# Cortex_M42 register map
Vendor: Arm Ltd.; Series: ARMv8.1-M Mainline; File version: 1.0.0
CPU: CM42 r0p0, little endian, MPU, FPU, double-precision FPU, DSP, 8 interrupt priority bits
Registers are 32-bit, read-write, reset 0x0 unless marked. A register's access mark holds for its fields unless they carry their own. Offsets are from the block's base; [hi:lo] are bit positions; {n}, {i} and the like mark numbered series.

## DIB — Debug Identification Block (ARMv8-M): software lock, debug authentication status and the SCS CoreSight architecture and type IDs.
Base 0xE000EFB0
Same registers: DIB_NS 0xE002EFB0
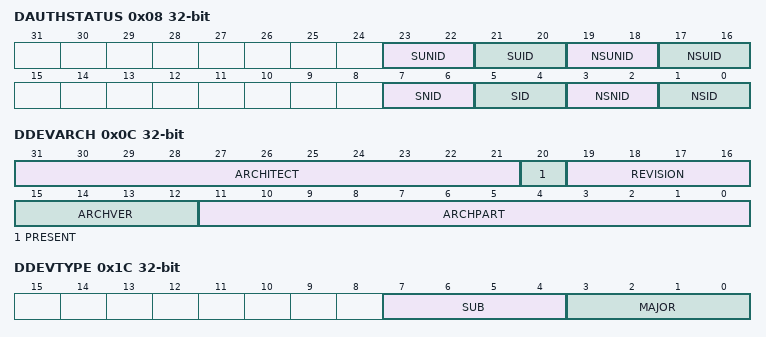
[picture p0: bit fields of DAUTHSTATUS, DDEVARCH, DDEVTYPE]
0x08 DAUTHSTATUS ro — Debug Authentication Status Register: which kinds of debug (invasive/non-invasive, Secure/Non-secure, unprivileged) are currently enabled.
  [23:22] SUNID — Secure unprivileged non-invasive debug: 2 = disabled, 3 = enabled.
  [21:20] SUID — Secure unprivileged invasive debug: 2 = disabled, 3 = enabled.
  [19:18] NSUNID — Non-secure unprivileged non-invasive debug: 2 = disabled, 3 = enabled.
  [17:16] NSUID — Non-secure unprivileged invasive debug (ARMv8.1-M UDE): 2 = disabled, 3 = enabled.
  [7:6] SNID — Secure non-invasive debug: 0 = not implemented, 2 = disabled, 3 = enabled.
  [5:4] SID — Secure invasive debug: 0 = not implemented, 2 = disabled, 3 = enabled.
  [3:2] NSNID — Non-secure non-invasive debug (trace): 0 = not implemented, 2 = disabled, 3 = enabled.
  [1:0] NSID — Non-secure invasive debug: 0 = not implemented, 2 = disabled, 3 = enabled.
0x0C DDEVARCH ro — SCS Device Architecture Register: CoreSight ARCHID of the debug architecture (0x2A04 = ARMv8-M debug) and the architect (Arm, 0x23B).
  [31:21] ARCHITECT — JEP106 code of the architect: 0x23B = Arm.
  [20] PRESENT — 1 = DDEVARCH is present and its contents are valid.
  [19:16] REVISION — Architecture revision.
  [15:12] ARCHVER — Architecture version: 2 = ARMv8-M debug architecture.
  [11:0] ARCHPART — Architecture part: 0xA04 = M-profile system control space (with ARCHVER 2 -> ARCHID 0x2A04, ARMv8-M debug).
0x1C DDEVTYPE ro — SCS Device Type Register: CoreSight major/sub type of the SCS (0x00 = processor system control).
  [7:4] SUB — Sub type: 0 for the SCS.
  [3:0] MAJOR — Major type: 0 = miscellaneous / processor system control.

## PWRMODCTL — Power Mode Control (Cortex-M55/M85/M52): the low-power state (ON / retention / OFF) requested for the core, EPU and RAM power domains when the processor sleeps.
Base 0xE001E300
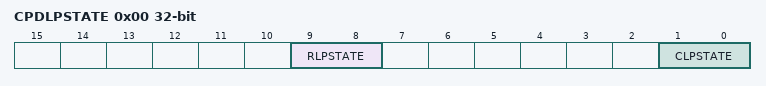
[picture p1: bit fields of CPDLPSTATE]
0x00 CPDLPSTATE — Core Power Domain Low Power State Register: the power state requested for the core, EPU (FPU/MVE) and RAM domains on deep sleep.
  [9:8] RLPSTATE — RAM (caches/TCM) low-power state: 0 = ON, 2 = retention, 3 = OFF.
  [1:0] CLPSTATE — Core low-power state requested on deep sleep: 0 = ON, 1 = ON with the clock stopped, 2 = retention, 3 = OFF.
0x04 DPDLPSTATE — Debug Power Domain Low Power State Register: the power state requested for the debug domain.
  [1:0] DLPSTATE — Debug power domain low-power state: 0 = ON, 2 = retention, 3 = OFF.

## EWIC_ISA — EWIC Interrupt Status Access: the processor-side view of the EWIC - set an event pending and read back the mask configuration.
Base 0xE001E400
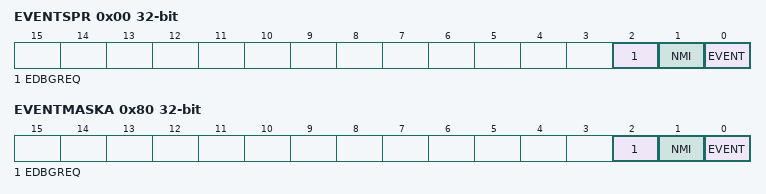
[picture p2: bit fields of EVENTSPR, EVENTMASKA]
0x00 EVENTSPR wo — Event Set Pending Register: software writes to latch an event as if it had arrived.
  [2] EDBGREQ — Write 1 to latch an external debug request.
  [1] NMI — Write 1 to latch an NMI.
  [0] EVENT — Write 1 to latch an EVENT.
0x80 EVENTMASKA ro — Event Mask A Register: read-only copy of EWIC_MASKA.
  [2] EDBGREQ — Wake on external debug request is enabled.
  [1] NMI — Wake on NMI is enabled.
  [0] EVENT — Wake on EVENT is enabled.
{0x80+4i} EVENTMASK{i} (i=1..15) ro — Event Mask Register n: read-only copy of EWIC_MASKn.
  [31:0] IRQ — Bit k = 1: wake on IRQ 32(n-1)+k is enabled.

## PRCCFGINF — Processor Configuration Information: indexed read access to the build-time configuration of the core (cache/TCM sizes, options).
Base 0xE001E700
0x00 CFGINFOSEL wo — Processor Configuration Information Selection Register: write the index of the configuration word to read from CFGINFORD.
  [31:0] SEL — Index of the configuration information word to read.
0x04 CFGINFORD ro — Processor Configuration Information Read Data Register: the configuration word selected by CFGINFOSEL.
  [31:0] DATA — Configuration information word.

## EWIC — External Wakeup Interrupt Controller: latches interrupt, NMI and event inputs while the processor is powered down and wakes it. Configure the masks before sleeping.
Base 0xE0047000
0x00 EWIC_CR — EWIC Control Register: global enable.
  [0] EN — EWIC enable. Set before powering down so wake-up events are latched.
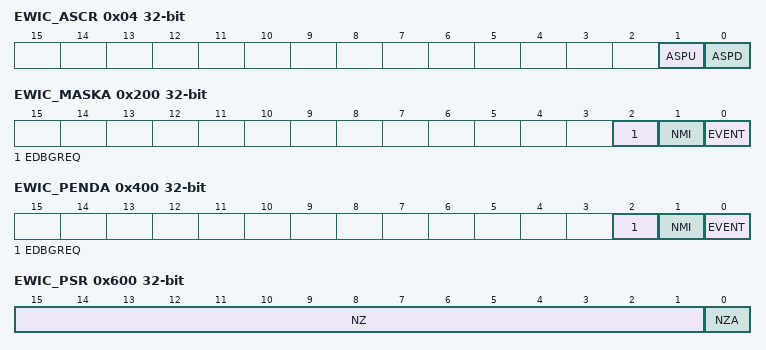
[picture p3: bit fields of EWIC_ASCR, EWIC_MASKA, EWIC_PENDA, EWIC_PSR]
0x04 EWIC_ASCR — EWIC Automatic Sequence Control Register: automatic mask/unmask sequencing on power-down and power-up.
  [1] ASPU — Automatic sequence on power-up: 1 = latched events are transferred to the NVIC automatically on power-up.
  [0] ASPD — Automatic sequence on power-down: 1 = the EWIC copies the NVIC enables into its masks automatically when the processor powers down.
0x08 EWIC_CLRMASK wo — EWIC Clear Mask Register: write to clear all mask registers.
  [31:0] CLRMASK — Write to clear all EWIC mask registers.
0x0C EWIC_NUMID ro — EWIC Event Number ID Register: how many events (interrupts plus NMI/EVENT/EDBGREQ) the EWIC handles.
  [15:0] NUMEVENT — Number of events supported.
0x200 EWIC_MASKA — EWIC Mask A Register: wake-up enables for the non-interrupt events (EVENT, NMI, EDBGREQ).
  [2] EDBGREQ — Wake on an external debug request.
  [1] NMI — Wake on NMI.
  [0] EVENT — Wake on the EVENT (RXEV) input.
{0x200+4i} EWIC_MASK{i} (i=1..15) — EWIC Mask Register n: bit k enables wake-up on IRQ 32(n-1)+k.
  [31:0] IRQ — Bit k = 1: wake on IRQ 32(n-1)+k.
0x400 EWIC_PENDA ro — EWIC Pend A Register: which non-interrupt events have been latched.
  [2] EDBGREQ — External debug request was latched.
  [1] NMI — NMI was latched.
  [0] EVENT — EVENT input was latched.
{0x400+4i} EWIC_PEND{i} (i=1..15) — EWIC Pend Register n: bit k = IRQ 32(n-1)+k has been latched while the processor was powered down.
  [31:0] IRQ — Bit k = 1: IRQ 32(n-1)+k was latched.
0x600 EWIC_PSR ro — EWIC Pend Summary Register: which PEND registers hold at least one latched event.
  [15:1] NZ — Bit n-1 = 1: EWIC_PENDn is non-zero.
  [0] NZA — EWIC_PENDA is non-zero.

## Notices in the file
Copyright 2026 Arm Limited. Licensed under the Apache License, Version 2.0.
Copyright 2026 Arm Limited. Licensed under the Apache License, Version 2.0 (the "License");
you may not use this file except in compliance with the License. You may obtain a copy of the License at
https://www.apache.org/licenses/LICENSE-2.0
Unless required by applicable law or agreed to in writing, software
distributed under the License is distributed on an "AS IS" BASIS, WITHOUT WARRANTIES OR CONDITIONS OF ANY KIND,
either express or implied. See the License for the specific language governing permissions and limitations under the License.
